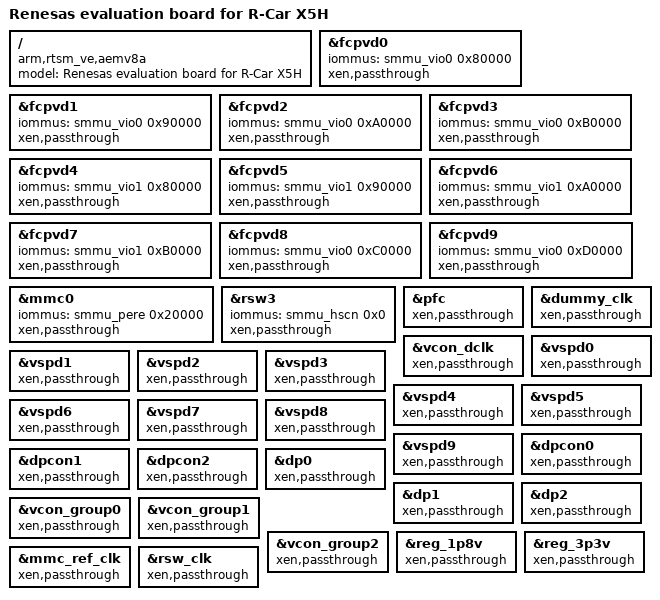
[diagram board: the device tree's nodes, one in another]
/dts-v1/;

#include "r8a78000-x5h.dts"
#include "chosen.dtsi"

/ {
	model = "Renesas evaluation board for R-Car X5H";
	compatible = "arm,rtsm_ve,aemv8a", "arm,vexpress";
};

/*=========================== Bus masters linked to IPMMUS ===================*/

&fcpvd0 { iommus = <&smmu_vio0 0x80000>; };
&fcpvd1 { iommus = <&smmu_vio0 0x90000>; };
&fcpvd2 { iommus = <&smmu_vio0 0xA0000>; };
&fcpvd3 { iommus = <&smmu_vio0 0xB0000>; };
&fcpvd4 { iommus = <&smmu_vio1 0x80000>; };
&fcpvd5 { iommus = <&smmu_vio1 0x90000>; };
&fcpvd6 { iommus = <&smmu_vio1 0xA0000>; };
&fcpvd7 { iommus = <&smmu_vio1 0xB0000>; };
&fcpvd8 { iommus = <&smmu_vio0 0xC0000>; };
&fcpvd9 { iommus = <&smmu_vio0 0xD0000>; };
&mmc0 { iommus = <&smmu_pere 0x20000>; };
&rsw3 { iommus = <&smmu_hscn 0x0>; };

/* ============================ Xen pass through section =====================*/

&pfc { xen,passthrough; };
&dummy_clk { xen,passthrough; };
&vcon_dclk { xen,passthrough; };
&fcpvd0 { xen,passthrough; };
&fcpvd1 { xen,passthrough; };
&fcpvd2 { xen,passthrough; };
&fcpvd3 { xen,passthrough; };
&fcpvd4 { xen,passthrough; };
&fcpvd5 { xen,passthrough; };
&fcpvd6 { xen,passthrough; };
&fcpvd7 { xen,passthrough; };
&fcpvd8 { xen,passthrough; };
&fcpvd9 { xen,passthrough; };
&vspd0 { xen,passthrough; };
&vspd1 { xen,passthrough; };
&vspd2 { xen,passthrough; };
&vspd3 { xen,passthrough; };
&vspd4 { xen,passthrough; };
&vspd5 { xen,passthrough; };
&vspd6 { xen,passthrough; };
&vspd7 { xen,passthrough; };
&vspd8 { xen,passthrough; };
&vspd9 { xen,passthrough; };
&dpcon0 { xen,passthrough; };
&dpcon1 { xen,passthrough; };
&dpcon2 { xen,passthrough; };
&dp0 { xen,passthrough; };
&dp1 { xen,passthrough; };
&dp2 { xen,passthrough; };
&vcon_group0 { xen,passthrough; };
&vcon_group1 { xen,passthrough; };
&vcon_group2 { xen,passthrough; };
&reg_1p8v { xen,passthrough; };
&reg_3p3v { xen,passthrough; };
&mmc_ref_clk { xen,passthrough; };
&mmc0 { xen,passthrough; };
&rsw_clk { xen,passthrough; };
&rsw3 { xen,passthrough; };
